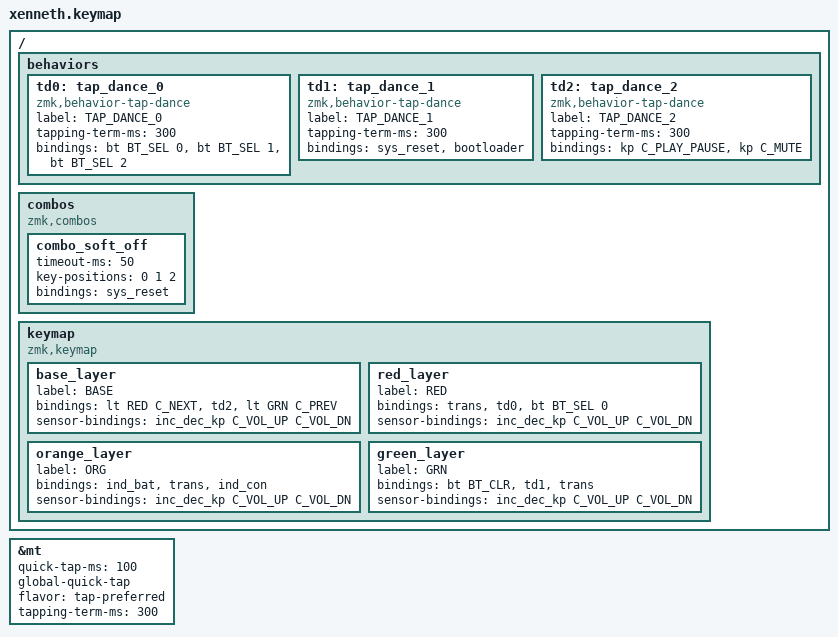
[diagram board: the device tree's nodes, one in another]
/*
 * Copyright (c) 2020 The ZMK Contributors
 *
 * SPDX-License-Identifier: MIT
 */

 #include <behaviors.dtsi>
 #include <dt-bindings/zmk/keys.h>
 #include <dt-bindings/zmk/bt.h>
 #include <dt-bindings/zmk/outputs.h>
 #include <behaviors/rgbled_widget.dtsi> 

 #define BASE 0
 #define RED  1
 #define ORG  2
 #define GRN  3
 
 &mt {
   quick-tap-ms = <100>;
   global-quick-tap;
   flavor = "tap-preferred";
   tapping-term-ms = <300>;
 };
 
 / {
    behaviors {
        td0: tap_dance_0 {
            compatible = "zmk,behavior-tap-dance";
            label = "TAP_DANCE_0";
            #binding-cells = <0>;
            tapping-term-ms = <300>;
            bindings = <&bt BT_SEL 0>, <&bt BT_SEL 1>, <&bt BT_SEL 2>;
        };
        td1: tap_dance_1 {
            compatible = "zmk,behavior-tap-dance";
            label = "TAP_DANCE_1";
            #binding-cells = <0>;
            tapping-term-ms = <300>;
            bindings = <&sys_reset>, <&bootloader>;
        };
        td2: tap_dance_2 {
            compatible = "zmk,behavior-tap-dance";
            label = "TAP_DANCE_2";
            #binding-cells = <0>;
            tapping-term-ms = <300>;
            bindings = <&kp C_PLAY_PAUSE>, <&kp C_MUTE>;
        };
    };
    combos {
        compatible = "zmk,combos";
        combo_soft_off {
            timeout-ms = <50>;
            key-positions = <0 1 2>;
            bindings = <&sys_reset>;
        };
    };
     keymap {
                 compatible = "zmk,keymap";
 
 // ▄▄▄▄▄▄▄▄▄▄▄▄▄▄▄▄▄▄▄▄▄▄▄▄▄▄▄▄▄▄▄▄▄▄▄▄▄▄▄▄▄
                 base_layer {
 // ┏━━━━━━━━━━━━━━━━━━━━━━━━━━━━━━━━━━━━━━━┓
                 label= "BASE"              ;
 // ┗━━━━━━━━━━━━━━━━━━━━━━━━━━━━━━━━━━━━━━━┛
 //              ┏━━━━━━━━━━━━┓
 //              ┃    Next    ┃
 //              ┣━━━━━━━━━━━━┫
 //              ┃ Play/Pause ┃
 //              ┣━━━━━━━━━━━━┫
 //              ┃  Previous  ┃ 
 //              ┗━━━━━━━━━━━━┛
 //
  bindings = <
 //
     &lt RED C_NEXT
     &td2
     &lt GRN C_PREV
         >;
     sensor-bindings = <&inc_dec_kp C_VOL_UP C_VOL_DN>;
                 };
 
 // ▄▄▄▄▄▄▄▄▄▄▄▄▄▄▄▄▄▄▄▄▄▄▄▄▄▄▄▄▄▄▄▄▄▄▄▄▄▄▄▄▄
 
                 red_layer {
 // ┏━━━━━━━━━━━━━━━━━━━━━━━━━━━━━━━━━━━━━━━┓
                 label= "RED"               ;
 // ┗━━━━━━━━━━━━━━━━━━━━━━━━━━━━━━━━━━━━━━━┛
 //              ┏━━━━━━━━━━━━┓
 //              ┃            ┃
 //              ┣━━━━━━━━━━━━┫
 //              ┃   BT Tap   ┃
 //              ┣━━━━━━━━━━━━┫
 //              ┃    BT1     ┃
 //              ┗━━━━━━━━━━━━┛
 //
  bindings = <
 //
     &trans
     &td0
     &bt BT_SEL 0   
         >;
     sensor-bindings = <&inc_dec_kp C_VOL_UP C_VOL_DN>;
                 };
 
 // ▄▄▄▄▄▄▄▄▄▄▄▄▄▄▄▄▄▄▄▄▄▄▄▄▄▄▄▄▄▄▄▄▄▄▄▄▄▄▄▄▄
 
                 orange_layer {
 // ┏━━━━━━━━━━━━━━━━━━━━━━━━━━━━━━━━━━━━━━━┓
                 label= "ORG"               ;
 // ┗━━━━━━━━━━━━━━━━━━━━━━━━━━━━━━━━━━━━━━━┛
 //              ┏━━━━━━━━━━━━┓
 //              ┃ BAT Level  ┃
 //              ┣━━━━━━━━━━━━┫
 //              ┃            ┃
 //              ┣━━━━━━━━━━━━┫
 //              ┃ BT Profile ┃
 //              ┗━━━━━━━━━━━━┛
 //
  bindings = <
 //
     &ind_bat
     &trans
     &ind_con
         >;
     sensor-bindings = <&inc_dec_kp C_VOL_UP C_VOL_DN>;
                 };
 
 // ▄▄▄▄▄▄▄▄▄▄▄▄▄▄▄▄▄▄▄▄▄▄▄▄▄▄▄▄▄▄▄▄▄▄▄▄▄▄▄▄▄
 
                 green_layer {
 // ┏━━━━━━━━━━━━━━━━━━━━━━━━━━━━━━━━━━━━━━━┓
                 label= "GRN"               ;
 // ┗━━━━━━━━━━━━━━━━━━━━━━━━━━━━━━━━━━━━━━━┛
 //              ┏━━━━━━━━━━━━┓
 //              ┃  BT Clear  ┃
 //              ┣━━━━━━━━━━━━┫
 //              ┃  Reset Tap ┃
 //              ┣━━━━━━━━━━━━┫
 //              ┃            ┃
 //              ┗━━━━━━━━━━━━┛
 //
  bindings = <
 //
     &bt BT_CLR
     &td1
     &trans
         >;
     sensor-bindings = <&inc_dec_kp C_VOL_UP C_VOL_DN>;
                 };
         };
 };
